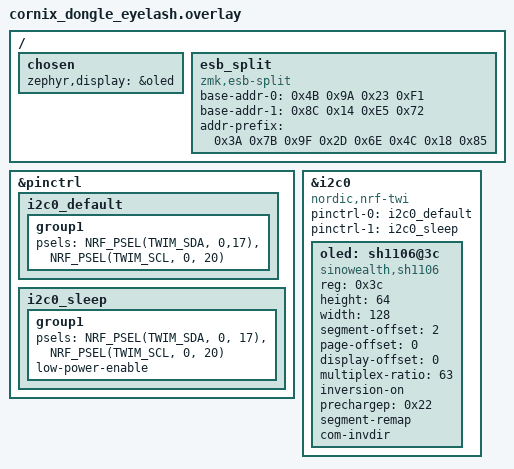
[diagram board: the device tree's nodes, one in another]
#include <dt-bindings/zmk/matrix_transform.h>

/{
    chosen {
        zephyr,display = &oled;
    };
};
// vim: set ft=dts :
&pinctrl {
    i2c0_default: i2c0_default {
        group1 {
            psels = <NRF_PSEL(TWIM_SDA, 0,17)>,
                <NRF_PSEL(TWIM_SCL, 0, 20)>;
        };
    };

    i2c0_sleep: i2c0_sleep {
        group1 {
            psels = <NRF_PSEL(TWIM_SDA, 0, 17)>,
                <NRF_PSEL(TWIM_SCL, 0, 20)>;
            low-power-enable;
        };
    };
};


&i2c0 {
	status = "okay";
	compatible = "nordic,nrf-twi";
    pinctrl-0 = <&i2c0_default>;
    pinctrl-1 = <&i2c0_sleep>;
	oled: sh1106@3c {
        compatible = "sinowealth,sh1106";
        reg = <0x3c>;
        height = <64>;

        // old lvgl
        //width = <129>;
        //segment-offset = <1>;

        //lvgl 9.x
        width = <128>;
        segment-offset = <2>;

        page-offset = <0>;
        display-offset = <0>;
        multiplex-ratio = <63>;
        inversion-on;
        prechargep = <0x22>;

        // comment to rotate 180
        segment-remap;
        com-invdir;
	};
};

/ {
    esb_split {
        compatible = "zmk,esb-split";
        // These are arbitrary default addresses.
        // Use different addresses for each set of devices in production.
        base-addr-0 = <0x4B 0x9A 0x23 0xF1>;
        base-addr-1 = <0x8C 0x14 0xE5 0x72>;
        addr-prefix = <0x3A 0x7B 0x9F 0x2D 0x6E 0x4C 0x18 0x85>;
    };
};

//vim: set ft=dts:
